# ESP32S31_RADIO register map
Vendor: Espressif; Series: ESP32-S31; File version: 3.52
Registers are 32-bit, read-write, no defined reset value unless marked. A register's access mark holds for its fields unless they carry their own. Offsets are from the block's base; [hi:lo] are bit positions; {n}, {i} and the like mark numbered series.

## BLE_HW_ACCELERATOR — Sparse ESP32-S31 BLE hardware-accelerator view. Complete ble_hw.c operations independently prove encryption and resolving-list engines in this physical block; complete BLE PHY initialization proves three additional initialization words. Cross-chip objects provide function identities only. Addresses, field geometry, values, ordering and predicates all come from ESP32-S31 bytes.
Base 0x20109800
0x00 INIT_CONFIG — Project-assigned name. BLE PHY initialization writes the complete finite image 0x000002F0. Inner semantics remain unknown.
  [31:0] VALUE — Project-assigned name.
0x04 ENCRYPT_START wo — Project-assigned name. r_ble_hw_encrypt_block writes the complete value 1 after publishing all encryption parameters.
  [31:0] COMMAND — Project-assigned name.
0x08 ENCRYPT_CONFIG — Project-assigned name. r_ble_hw_encrypt_block writes the finite complete image 1 before publishing buffer pointers.
  [31:0] VALUE — Project-assigned name.
0x0C ENCRYPT_BLOCK_LENGTH — Project-assigned name. r_ble_hw_encrypt_block writes the finite complete image 16.
  [31:0] BYTES — Project-assigned name.
{0x10+4i} ENCRYPT_KEY_WORD_{i} wo (i=0..3) — Project-assigned name. Little-endian word assembled from encryption-key argument bytes {4i} through {4i+3}.
  [31:0] VALUE — Project-assigned name.
0x20 ENCRYPT_INPUT_BUFFER_ADDRESS wo — Project-assigned name. Complete pointer image equal to the r_ble_hw_encrypt_block argument base plus 16.
  [31:0] ADDRESS — Project-assigned name.
0x24 ENCRYPT_OUTPUT_BUFFER_ADDRESS wo — Project-assigned name. Complete pointer image equal to the r_ble_hw_encrypt_block argument base plus 32.
  [31:0] ADDRESS — Project-assigned name.
0x80 RESOLV_SEARCH_START wo — Project-assigned name. r_ble_hw_resolv_list_search writes the complete finite image 1 after publishing its inputs.
  [31:0] COMMAND — Project-assigned name.
0x88 RESOLV_LIST_ARGUMENT wo — Project-assigned name. Complete first argument published by r_ble_hw_resolv_list_search.
  [31:0] VALUE — Project-assigned name.
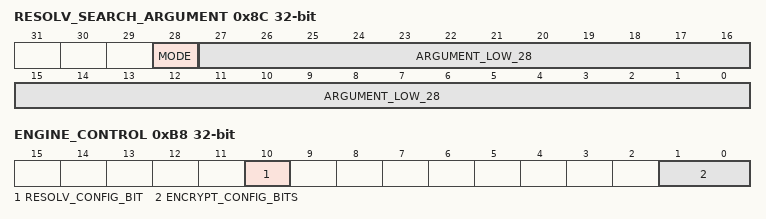
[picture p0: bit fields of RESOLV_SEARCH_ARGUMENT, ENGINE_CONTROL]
0x8C RESOLV_SEARCH_ARGUMENT wo — Project-assigned name. Second search argument in bits 0..27 and a Boolean third-argument mode in bit 28.
  [28] MODE — Project-assigned name.
  [27:0] ARGUMENT_LOW_28 — Project-assigned name.
0xA0 RESOLV_RESULT_METADATA ro — Project-assigned name. Search result word; r_ble_hw_resolv_list_search returns bits 8..15 through its fourth argument. Other bits remain unknown.
  [15:8] RESULT_BYTE — Project-assigned name.
0xA4 RESOLV_RESULT_POINTER_OFFSET ro — Project-assigned name. Search result combined with SRAM prefix 0x2F000000 to form the returned pointer. The exact encoded width remains unknown.
  [31:0] VALUE — Project-assigned name.
0xA8 RESOLV_RESULT_PRESENT ro — Project-assigned name. Complete word tested for zero before the result pointer and metadata are consumed.
  [31:0] VALUE — Project-assigned name.
0xB8 ENGINE_CONTROL — Project-assigned name. Shared control word: encryption sets bits 0..1 through RMW; resolving-list search writes the finite complete image 0x400.
  [10] RESOLV_CONFIG_BIT — Project-assigned name.
  [1:0] ENCRYPT_CONFIG_BITS — Project-assigned name.
0xBC RESOLV_STATUS ro — Project-assigned name. r_ble_hw_resolv_list_search polls bit 2 with a finite software timeout.
  [2] COMPLETE — Project-assigned name.
0xC4 ENCRYPT_COMPLETION_STATUS ro — Project-assigned name. r_ble_hw_encrypt_block polls the complete word until nonzero, with a finite software timeout. Inner encoding remains unknown.
  [31:0] VALUE — Project-assigned name.
0xCC INIT_SRAM_REGION_0 — Project-assigned name. BLE PHY initialization writes the complete finite image 0x2F080000. Inner semantics remain unknown.
  [31:0] VALUE — Project-assigned name.
0xD0 INIT_SRAM_REGION_1 — Project-assigned name. BLE PHY initialization writes the complete finite image 0x2F000000. Inner semantics remain unknown.
  [31:0] VALUE — Project-assigned name.
